# HDSC_HC32F165 register map
Vendor: HDSC; Series: ARMCM0P; File version: 1.0
CPU: CM0P r0p1, little endian, MPU, FPU, 4 interrupt priority bits
Registers are 32-bit, read-write, reset 0x0 unless marked. A register's access mark holds for its fields unless they carry their own. Offsets are from the block's base; [hi:lo] are bit positions; {n}, {i} and the like mark numbered series.

## EMB0 — desc EMB
Base 0x40017C00
Same registers: EMB1 0x40017C20
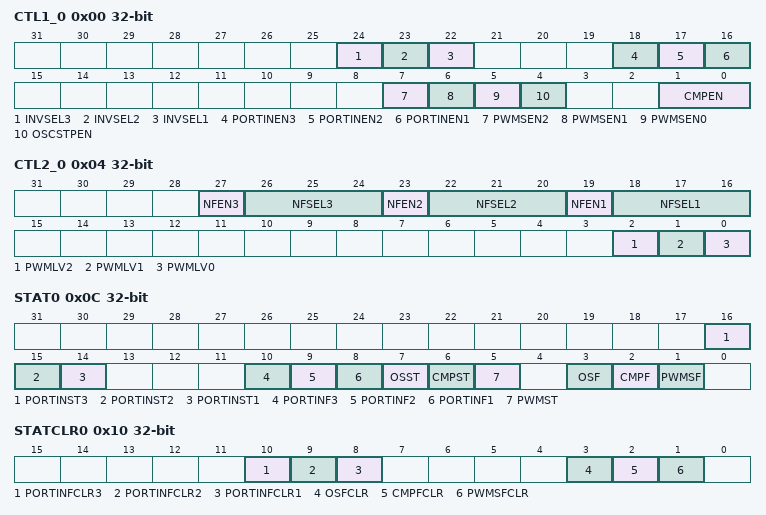
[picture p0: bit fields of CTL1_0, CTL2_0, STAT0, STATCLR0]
0x00 CTL1_0
  [24] INVSEL3, [23] INVSEL2, [22] INVSEL1, [18] PORTINEN3, [17] PORTINEN2, [16] PORTINEN1, [7] PWMSEN2, [6] PWMSEN1, [5] PWMSEN0, [4] OSCSTPEN, [1:0] CMPEN
0x04 CTL2_0
  [27] NFEN3, [26:24] NFSEL3, [23] NFEN2, [22:20] NFSEL2, [19] NFEN1, [18:16] NFSEL1, [2] PWMLV2, [1] PWMLV1, [0] PWMLV0
0x08 SOE0
  [0] SOE
0x0C STAT0 ro
  [16] PORTINST3 rw, [15] PORTINST2 rw, [14] PORTINST1 rw, [10] PORTINF3, [9] PORTINF2, [8] PORTINF1, [7] OSST, [6] CMPST, [5] PWMST, [3] OSF, [2] CMPF, [1] PWMSF
0x10 STATCLR0 wo
  [10] PORTINFCLR3, [9] PORTINFCLR2, [8] PORTINFCLR1, [3] OSFCLR, [2] CMPFCLR, [1] PWMSFCLR
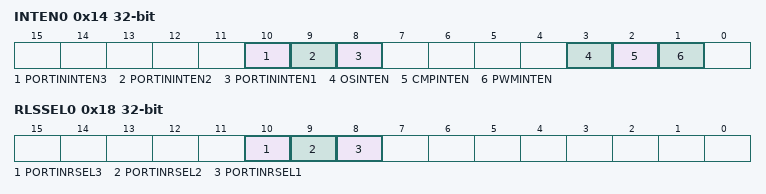
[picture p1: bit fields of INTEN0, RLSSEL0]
0x14 INTEN0
  [10] PORTININTEN3, [9] PORTININTEN2, [8] PORTININTEN1, [3] OSINTEN, [2] CMPINTEN, [1] PWMINTEN
0x18 RLSSEL0
  [10] PORTINRSEL3, [9] PORTINRSEL2, [8] PORTINRSEL1
0x3C ECSR
  [1:0] EMBVAL

## FCM
Base 0x40048400
0x00 LVR
  [15:0] LVR
0x04 UVR
  [15:0] UVR
0x08 CNTR ro
  [15:0] CNTR
0x0C STR
  [0] START
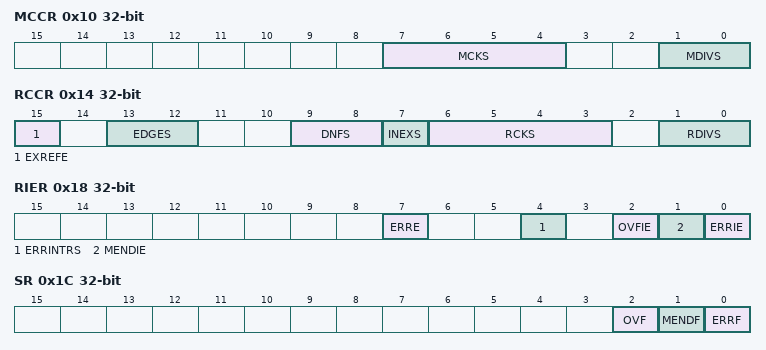
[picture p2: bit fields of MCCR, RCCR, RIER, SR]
0x10 MCCR
  [7:4] MCKS, [1:0] MDIVS
0x14 RCCR
  [15] EXREFE, [13:12] EDGES, [9:8] DNFS, [7] INEXS, [6:3] RCKS, [1:0] RDIVS
0x18 RIER
  [7] ERRE, [4] ERRINTRS, [2] OVFIE, [1] MENDIE, [0] ERRIE
0x1C SR ro
  [2] OVF, [1] MENDF, [0] ERRF
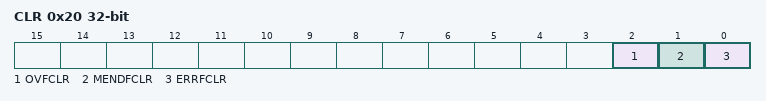
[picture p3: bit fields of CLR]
0x20 CLR wo
  [2] OVFCLR, [1] MENDFCLR, [0] ERRFCLR

## I2C1 — desc I2C
Base 0x4004E000
Same registers: I2C2 0x4004E400
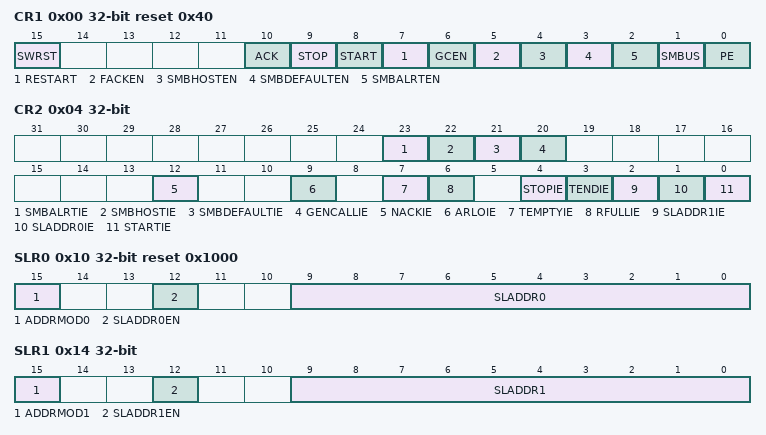
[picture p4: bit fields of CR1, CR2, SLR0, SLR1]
0x00 CR1 reset 0x40
  [15] SWRST, [10] ACK, [9] STOP, [8] START, [7] RESTART, [6] GCEN, [5] FACKEN, [4] SMBHOSTEN, [3] SMBDEFAULTEN, [2] SMBALRTEN, [1] SMBUS, [0] PE
0x04 CR2
  [23] SMBALRTIE, [22] SMBHOSTIE, [21] SMBDEFAULTIE, [20] GENCALLIE, [12] NACKIE, [9] ARLOIE, [7] TEMPTYIE, [6] RFULLIE, [4] STOPIE, [3] TENDIE, [2] SLADDR1IE, [1] SLADDR0IE, [0] STARTIE
0x0C CR4 reset 0x300307
  [10] BUSWAIT
0x10 SLR0 reset 0x1000
  [15] ADDRMOD0, [12] SLADDR0EN, [9:0] SLADDR0
0x14 SLR1
  [15] ADDRMOD1, [12] SLADDR1EN, [9:0] SLADDR1
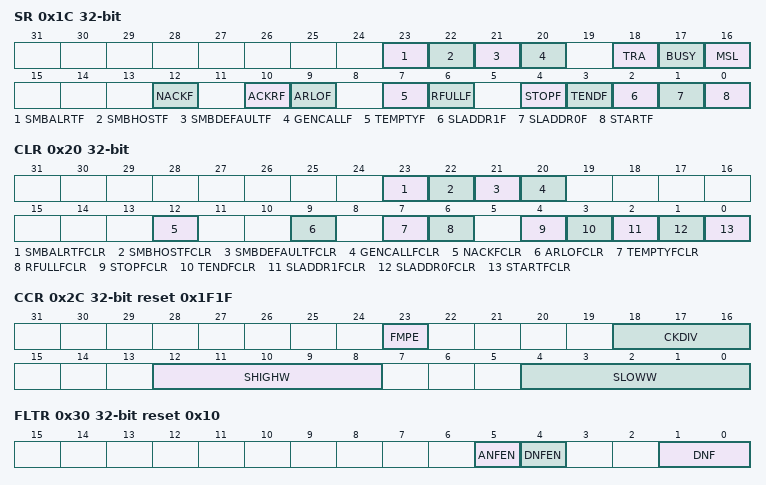
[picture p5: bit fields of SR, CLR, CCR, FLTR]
0x1C SR ro
  [23] SMBALRTF, [22] SMBHOSTF, [21] SMBDEFAULTF, [20] GENCALLF, [18] TRA rw, [17] BUSY, [16] MSL rw, [12] NACKF, [10] ACKRF, [9] ARLOF, [7] TEMPTYF, [6] RFULLF, [4] STOPF, [3] TENDF, [2] SLADDR1F, [1] SLADDR0F, [0] STARTF
0x20 CLR wo
  [23] SMBALRTFCLR, [22] SMBHOSTFCLR, [21] SMBDEFAULTFCLR, [20] GENCALLFCLR, [12] NACKFCLR, [9] ARLOFCLR, [7] TEMPTYFCLR, [6] RFULLFCLR, [4] STOPFCLR, [3] TENDFCLR, [2] SLADDR1FCLR, [1] SLADDR0FCLR, [0] STARTFCLR
0x24 DTR reset 0xFF
  [7:0] DT
0x28 DRR
  [7:0] DR
0x2C CCR reset 0x1F1F
  [23] FMPE, [18:16] CKDIV, [12:8] SHIGHW, [4:0] SLOWW
0x30 FLTR reset 0x10
  [5] ANFEN, [4] DNFEN, [1:0] DNF

## ICG
Base 0x000000C0
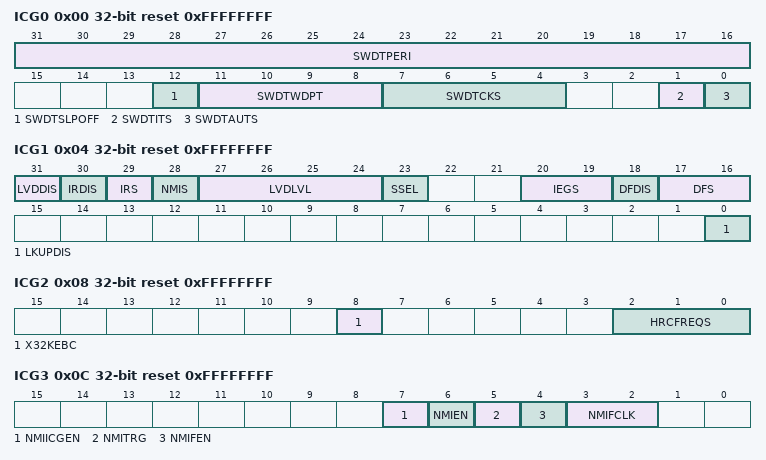
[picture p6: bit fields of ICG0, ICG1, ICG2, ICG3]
0x00 ICG0 ro reset 0xFFFFFFFF
  [31:16] SWDTPERI, [12] SWDTSLPOFF, [11:8] SWDTWDPT, [7:4] SWDTCKS, [1] SWDTITS, [0] SWDTAUTS
0x04 ICG1 ro reset 0xFFFFFFFF
  [31] LVDDIS, [30] IRDIS, [29] IRS, [28] NMIS, [27:24] LVDLVL rw, [23] SSEL, [20:19] IEGS, [18] DFDIS, [17:16] DFS, [0] LKUPDIS
0x08 ICG2 ro reset 0xFFFFFFFF
  [8] X32KEBC, [2:0] HRCFREQS
0x0C ICG3 ro reset 0xFFFFFFFF
  [7] NMIICGEN, [6] NMIEN, [5] NMITRG, [4] NMIFEN, [3:2] NMIFCLK
0x10 ICG4 ro reset 0xFFFFFFFF
0x14 ICG5 ro reset 0xFFFFFFFF
0x18 ICG6 ro reset 0xFFFFFFFF (reset mask 0x0)
  [32:28] ICG10, [32:24] ICG9, [32:20] ICG8, [3:2] NMIFCLK

## INTC
Base 0x40051000
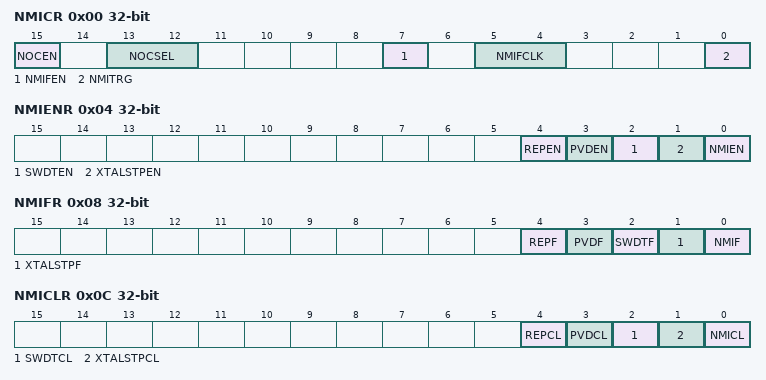
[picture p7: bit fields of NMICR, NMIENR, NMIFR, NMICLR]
0x00 NMICR
  [15] NOCEN, [13:12] NOCSEL, [7] NMIFEN, [5:4] NMIFCLK, [0] NMITRG
0x04 NMIENR
  [4] REPEN, [3] PVDEN, [2] SWDTEN, [1] XTALSTPEN, [0] NMIEN
0x08 NMIFR ro
  [4] REPF, [3] PVDF, [2] SWDTF, [1] XTALSTPF, [0] NMIF
0x0C NMICLR
  [4] REPCL, [3] PVDCL, [2] SWDTCL, [1] XTALSTPCL, [0] NMICL
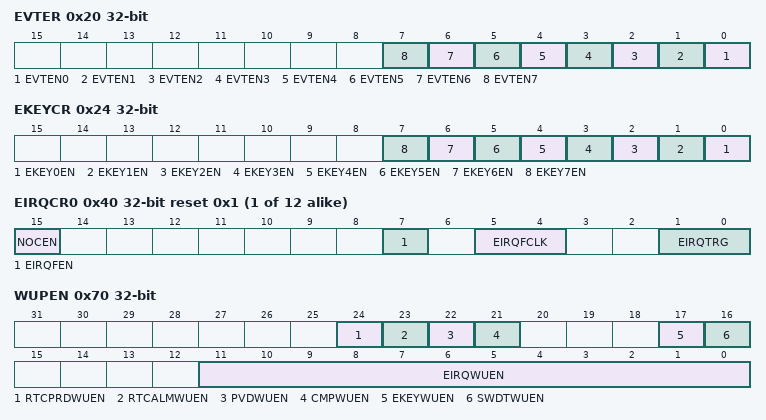
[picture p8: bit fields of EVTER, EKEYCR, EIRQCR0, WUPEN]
0x20 EVTER
  [n] EVTEN{n} (n=0..7)
0x24 EKEYCR
  [n] EKEY{n}EN (n=0..7)
0x3C FPRCR
  [7:0] FPRC
{0x40+4i} EIRQCR{i} reset 0x1 (i=0..11)
  [15] NOCEN, [7] EIRQFEN, [5:4] EIRQFCLK, [1:0] EIRQTRG
0x70 WUPEN
  [24] RTCPRDWUEN, [23] RTCALMWUEN, [22] PVDWUEN, [21] CMPWUEN, [17] EKEYWUEN, [16] SWDTWUEN, [11:0] EIRQWUEN
0x74 EIRQFR
  [11:0] EIRQF
0x78 EIRQCLR
  [11:0] EIRQCL
{0x80+4i} ISELAR{i} (i=8..23)
  [4:0] ISEL
{0x80+4i} ISELBR{i} (i=24..31)
  [23:1] ISEL
